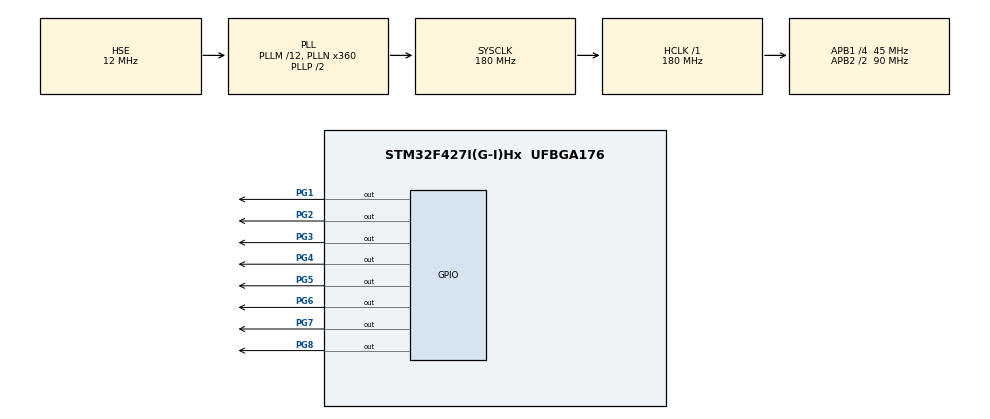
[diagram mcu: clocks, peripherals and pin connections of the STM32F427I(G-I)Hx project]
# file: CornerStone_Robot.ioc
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Mcu.Family=STM32F4
Mcu.Name=STM32F427I(G-I)Hx
Mcu.Package=UFBGA176
NVIC.PriorityGroup=NVIC_PRIORITYGROUP_4
PA13.Signal=SYS_JTMS-SWDIO
PA14.Signal=SYS_JTCK-SWCLK
PG1.PinState=GPIO_PIN_SET
PG1.Signal=GPIO_Output
PG2.PinState=GPIO_PIN_SET
PG2.Signal=GPIO_Output
PG3.PinState=GPIO_PIN_SET
PG3.Signal=GPIO_Output
PG4.PinState=GPIO_PIN_SET
PG4.Signal=GPIO_Output
PG5.PinState=GPIO_PIN_SET
PG5.Signal=GPIO_Output
PG6.PinState=GPIO_PIN_SET
PG6.Signal=GPIO_Output
PG7.PinState=GPIO_PIN_SET
PG7.Signal=GPIO_Output
PG8.GPIO_PuPd=GPIO_NOPULL
PG8.GPIO_Speed=GPIO_SPEED_FREQ_LOW
PG8.PinState=GPIO_PIN_SET
PG8.Signal=GPIO_Output
PH0/OSC_IN.Mode=HSE-External-Oscillator
PH0/OSC_IN.Signal=RCC_OSC_IN
PH1/OSC_OUT.Mode=HSE-External-Oscillator
PH1/OSC_OUT.Signal=RCC_OSC_OUT
ProjectManager.HeapSize=0x200
ProjectManager.StackSize=0x400
ProjectManager.TargetToolchain=STM32CubeIDE
RCC.48MHZClocksFreq_Value=45000000
RCC.AHBFreq_Value=180000000
RCC.APB1CLKDivider=RCC_HCLK_DIV4
RCC.APB1Freq_Value=45000000
RCC.APB1TimFreq_Value=90000000
RCC.APB2CLKDivider=RCC_HCLK_DIV2
RCC.APB2Freq_Value=90000000
RCC.APB2TimFreq_Value=180000000
RCC.CortexFreq_Value=180000000
RCC.HCLKFreq_Value=180000000
RCC.HSE_VALUE=12000000
RCC.HSI_VALUE=16000000
RCC.LSE_VALUE=32768
RCC.PLLM=12
RCC.PLLN=360
RCC.PLLQ=8
RCC.PLLSAIN=192
RCC.PLLSourceVirtual=RCC_PLLSOURCE_HSE
RCC.RCC_MCODiv2=RCC_MCODIV_2
RCC.RCC_RTC_Clock_Source_FROM_HSE=RCC_RTCCLKSOURCE_HSE_DIV12
RCC.SYSCLKFreq_VALUE=180000000
RCC.SYSCLKSource=RCC_SYSCLKSOURCE_PLLCLK
RCC.VCOOutputFreq_Value=360000000
board=custom

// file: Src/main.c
/* USER CODE BEGIN Header */
/**
  ******************************************************************************
  * @file           : main.c
  * @brief          : Main program body
  ******************************************************************************
  * @attention
  *
  * Copyright (c) 2026 STMicroelectronics.
  * All rights reserved.
  *
  * This software is licensed under terms that can be found in the LICENSE file
  * in the root directory of this software component.
  * If no LICENSE file comes with this software, it is provided AS-IS.
  *
  ******************************************************************************
  */
/* USER CODE END Header */
#include "main.h"

/* USER CODE BEGIN Includes */
#include "led_app.h"
/* USER CODE END Includes */

void SystemClock_Config(void);
static void MX_GPIO_Init(void);

int main(void)
{

  /* MCU Configuration--------------------------------------------------------*/

  /* Reset of all peripherals, Initializes the Flash interface and the Systick. */
  HAL_Init();

  /* Configure the system clock */
  SystemClock_Config();

  /* Initialize all configured peripherals */
  MX_GPIO_Init();
  /* USER CODE BEGIN 2 */
  LED_App_Init();
  /* USER CODE END 2 */

  /* Infinite loop */
  while (1)
  {

    /* USER CODE BEGIN 3 */
    LED_App_Step();
  }
  /* USER CODE END 3 */
}

void SystemClock_Config(void)
{
  RCC_OscInitTypeDef RCC_OscInitStruct = {0};
  RCC_ClkInitTypeDef RCC_ClkInitStruct = {0};

  /** Configure the main internal regulator output voltage
  */
  __HAL_RCC_PWR_CLK_ENABLE();
  __HAL_PWR_VOLTAGESCALING_CONFIG(PWR_REGULATOR_VOLTAGE_SCALE1);

  /** Initializes the RCC Oscillators according to the specified parameters
  * in the RCC_OscInitTypeDef structure.
  */
  RCC_OscInitStruct.OscillatorType = RCC_OSCILLATORTYPE_HSE;
  RCC_OscInitStruct.HSEState = RCC_HSE_ON;
  RCC_OscInitStruct.PLL.PLLState = RCC_PLL_ON;
  RCC_OscInitStruct.PLL.PLLSource = RCC_PLLSOURCE_HSE;
  RCC_OscInitStruct.PLL.PLLM = 12;
  RCC_OscInitStruct.PLL.PLLN = 360;
  RCC_OscInitStruct.PLL.PLLP = RCC_PLLP_DIV2;
  RCC_OscInitStruct.PLL.PLLQ = 8;
  if (HAL_RCC_OscConfig(&RCC_OscInitStruct) != HAL_OK)
  {
    Error_Handler();
  }

  /** Activate the Over-Drive mode
  */
  if (HAL_PWREx_EnableOverDrive() != HAL_OK)
  {
    Error_Handler();
  }

  /** Initializes the CPU, AHB and APB buses clocks
  */
  RCC_ClkInitStruct.ClockType = RCC_CLOCKTYPE_HCLK|RCC_CLOCKTYPE_SYSCLK
                              |RCC_CLOCKTYPE_PCLK1|RCC_CLOCKTYPE_PCLK2;
  RCC_ClkInitStruct.SYSCLKSource = RCC_SYSCLKSOURCE_PLLCLK;
  RCC_ClkInitStruct.AHBCLKDivider = RCC_SYSCLK_DIV1;
  RCC_ClkInitStruct.APB1CLKDivider = RCC_HCLK_DIV4;
  RCC_ClkInitStruct.APB2CLKDivider = RCC_HCLK_DIV2;

  if (HAL_RCC_ClockConfig(&RCC_ClkInitStruct, FLASH_LATENCY_5) != HAL_OK)
  {
    Error_Handler();
  }
}

static void MX_GPIO_Init(void)
{
  GPIO_InitTypeDef GPIO_InitStruct = {0};

  /* GPIO Ports Clock Enable */
  __HAL_RCC_GPIOA_CLK_ENABLE();
  __HAL_RCC_GPIOH_CLK_ENABLE();
  __HAL_RCC_GPIOG_CLK_ENABLE();

  /*Configure GPIO pin Output Level */
  HAL_GPIO_WritePin(GPIOG, GPIO_PIN_8|GPIO_PIN_7|GPIO_PIN_6|GPIO_PIN_5
                          |GPIO_PIN_4|GPIO_PIN_3|GPIO_PIN_2|GPIO_PIN_1, GPIO_PIN_SET);

  /*Configure GPIO pins : PG8 PG7 PG6 PG5
                           PG4 PG3 PG2 PG1 */
  GPIO_InitStruct.Pin = GPIO_PIN_8|GPIO_PIN_7|GPIO_PIN_6|GPIO_PIN_5
                          |GPIO_PIN_4|GPIO_PIN_3|GPIO_PIN_2|GPIO_PIN_1;
  GPIO_InitStruct.Mode = GPIO_MODE_OUTPUT_PP;
  GPIO_InitStruct.Pull = GPIO_NOPULL;
  GPIO_InitStruct.Speed = GPIO_SPEED_FREQ_LOW;
  HAL_GPIO_Init(GPIOG, &GPIO_InitStruct);

}

void Error_Handler(void)
{
  __disable_irq();
  while (1)
  {
  }
}
